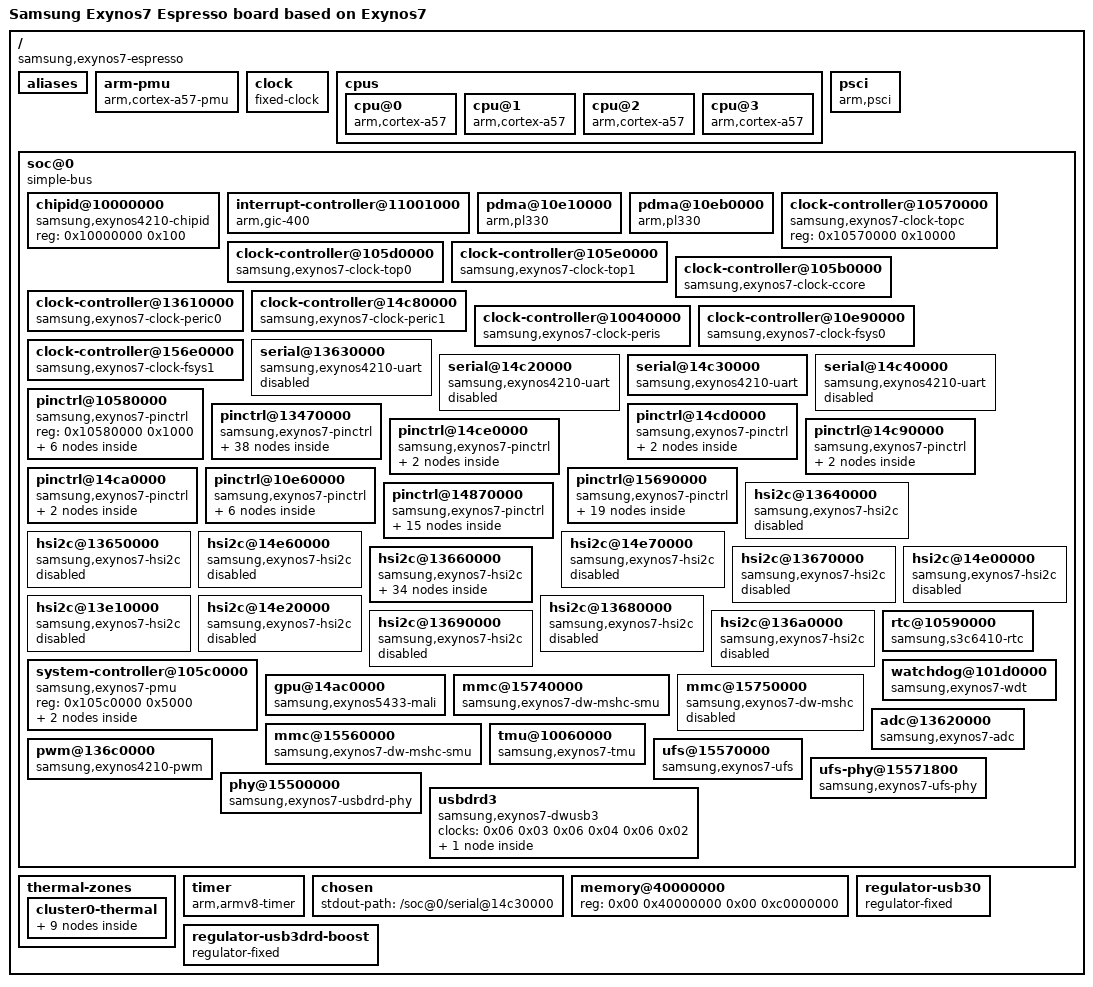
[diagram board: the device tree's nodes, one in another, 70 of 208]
/dts-v1/;

/ {
	compatible = "samsung,exynos7-espresso", "samsung,exynos7";
	interrupt-parent = <0x01>;
	#address-cells = <0x02>;
	#size-cells = <0x02>;
	model = "Samsung Exynos7 Espresso board based on Exynos7";

	aliases {
		pinctrl0 = "/soc@0/pinctrl@10580000";
		pinctrl1 = "/soc@0/pinctrl@13470000";
		pinctrl2 = "/soc@0/pinctrl@14cd0000";
		pinctrl3 = "/soc@0/pinctrl@14ce0000";
		pinctrl4 = "/soc@0/pinctrl@14c90000";
		pinctrl5 = "/soc@0/pinctrl@14ca0000";
		pinctrl6 = "/soc@0/pinctrl@10e60000";
		pinctrl7 = "/soc@0/pinctrl@15690000";
		pinctrl8 = "/soc@0/pinctrl@14870000";
		tmuctrl0 = "/soc@0/tmu@10060000";
		serial0 = "/soc@0/serial@14c30000";
		mshc0 = "/soc@0/mmc@15740000";
		mshc2 = "/soc@0/mmc@15560000";
	};

	arm-pmu {
		compatible = "arm,cortex-a57-pmu";
		interrupts = <0x00 0x38 0x04 0x00 0x39 0x04 0x00 0x3a 0x04 0x00 0x3b 0x04>;
		interrupt-affinity = <0x02 0x03 0x04 0x05>;
	};

	clock {
		compatible = "fixed-clock";
		clock-output-names = "fin_pll";
		#clock-cells = <0x00>;
		clock-frequency = <0x16e3600>;
		phandle = <0x07>;
	};

	cpus {
		#address-cells = <0x01>;
		#size-cells = <0x00>;

		cpu@0 {
			device_type = "cpu";
			compatible = "arm,cortex-a57";
			reg = <0x00>;
			enable-method = "psci";
			phandle = <0x02>;
		};

		cpu@1 {
			device_type = "cpu";
			compatible = "arm,cortex-a57";
			reg = <0x01>;
			enable-method = "psci";
			phandle = <0x03>;
		};

		cpu@2 {
			device_type = "cpu";
			compatible = "arm,cortex-a57";
			reg = <0x02>;
			enable-method = "psci";
			phandle = <0x04>;
		};

		cpu@3 {
			device_type = "cpu";
			compatible = "arm,cortex-a57";
			reg = <0x03>;
			enable-method = "psci";
			phandle = <0x05>;
		};
	};

	psci {
		compatible = "arm,psci";
		method = "smc";
		cpu_off = <0x84000002>;
		cpu_on = <0xc4000003>;
	};

	soc@0 {
		compatible = "simple-bus";
		#address-cells = <0x01>;
		#size-cells = <0x01>;
		ranges = <0x00 0x00 0x00 0x18000000>;
		phandle = <0x39>;

		chipid@10000000 {
			compatible = "samsung,exynos4210-chipid";
			reg = <0x10000000 0x100>;
		};

		interrupt-controller@11001000 {
			compatible = "arm,gic-400";
			#interrupt-cells = <0x03>;
			#address-cells = <0x00>;
			interrupt-controller;
			reg = <0x11001000 0x1000 0x11002000 0x2000 0x11004000 0x2000 0x11006000 0x2000>;
			phandle = <0x01>;
		};

		pdma@10e10000 {
			compatible = "arm,pl330", "arm,primecell";
			reg = <0x10e10000 0x1000>;
			interrupts = <0x00 0xe1 0x04>;
			clocks = <0x06 0x09>;
			clock-names = "apb_pclk";
			#dma-cells = <0x01>;
			#dma-channels = <0x08>;
			#dma-requests = <0x20>;
			phandle = <0x3a>;
		};

		pdma@10eb0000 {
			compatible = "arm,pl330", "arm,primecell";
			reg = <0x10eb0000 0x1000>;
			interrupts = <0x00 0xe2 0x04>;
			clocks = <0x06 0x0a>;
			clock-names = "apb_pclk";
			#dma-cells = <0x01>;
			#dma-channels = <0x08>;
			#dma-requests = <0x20>;
			phandle = <0x3b>;
		};

		clock-controller@10570000 {
			compatible = "samsung,exynos7-clock-topc";
			reg = <0x10570000 0x10000>;
			#clock-cells = <0x01>;
			phandle = <0x08>;
		};

		clock-controller@105d0000 {
			compatible = "samsung,exynos7-clock-top0";
			reg = <0x105d0000 0xb000>;
			#clock-cells = <0x01>;
			clocks = <0x07 0x08 0x02 0x08 0x03 0x08 0x04 0x08 0x05>;
			clock-names = "fin_pll", "dout_sclk_bus0_pll", "dout_sclk_bus1_pll", "dout_sclk_cc_pll", "dout_sclk_mfc_pll";
			phandle = <0x09>;
		};

		clock-controller@105e0000 {
			compatible = "samsung,exynos7-clock-top1";
			reg = <0x105e0000 0xb000>;
			#clock-cells = <0x01>;
			clocks = <0x07 0x08 0x02 0x08 0x03 0x08 0x04 0x08 0x05>;
			clock-names = "fin_pll", "dout_sclk_bus0_pll", "dout_sclk_bus1_pll", "dout_sclk_cc_pll", "dout_sclk_mfc_pll";
			phandle = <0x0a>;
		};

		clock-controller@105b0000 {
			compatible = "samsung,exynos7-clock-ccore";
			reg = <0x105b0000 0xd00>;
			#clock-cells = <0x01>;
			clocks = <0x07 0x08 0x06>;
			clock-names = "fin_pll", "dout_aclk_ccore_133";
			phandle = <0x1c>;
		};

		clock-controller@13610000 {
			compatible = "samsung,exynos7-clock-peric0";
			reg = <0x13610000 0xd00>;
			#clock-cells = <0x01>;
			clocks = <0x07 0x09 0x02 0x09 0x03>;
			clock-names = "fin_pll", "dout_aclk_peric0_66", "sclk_uart0";
			phandle = <0x0b>;
		};

		clock-controller@14c80000 {
			compatible = "samsung,exynos7-clock-peric1";
			reg = <0x14c80000 0xd00>;
			#clock-cells = <0x01>;
			clocks = <0x07 0x09 0x01 0x09 0x04 0x09 0x05 0x09 0x06>;
			clock-names = "fin_pll", "dout_aclk_peric1_66", "sclk_uart1", "sclk_uart2", "sclk_uart3";
			phandle = <0x0c>;
		};

		clock-controller@10040000 {
			compatible = "samsung,exynos7-clock-peris";
			reg = <0x10040000 0xd00>;
			#clock-cells = <0x01>;
			clocks = <0x07 0x08 0x01>;
			clock-names = "fin_pll", "dout_aclk_peris_66";
			phandle = <0x1e>;
		};

		clock-controller@10e90000 {
			compatible = "samsung,exynos7-clock-fsys0";
			reg = <0x10e90000 0xd00>;
			#clock-cells = <0x01>;
			clocks = <0x07 0x0a 0x02 0x0a 0x03>;
			clock-names = "fin_pll", "dout_aclk_fsys0_200", "dout_sclk_mmc2";
			phandle = <0x06>;
		};

		clock-controller@156e0000 {
			compatible = "samsung,exynos7-clock-fsys1";
			reg = <0x156e0000 0xd00>;
			#clock-cells = <0x01>;
			clocks = <0x07 0x0a 0x01 0x0a 0x05 0x0a 0x04 0x0a 0x0e 0x0a 0x10 0x0a 0x11>;
			clock-names = "fin_pll", "dout_aclk_fsys1_200", "dout_sclk_mmc0", "dout_sclk_mmc1", "dout_sclk_ufsunipro20", "dout_sclk_phy_fsys1", "dout_sclk_phy_fsys1_26m";
			phandle = <0x20>;
		};

		serial@13630000 {
			compatible = "samsung,exynos4210-uart";
			reg = <0x13630000 0x100>;
			interrupts = <0x00 0x1b8 0x04>;
			clocks = <0x0b 0x01 0x0b 0x02>;
			clock-names = "uart", "clk_uart_baud0";
			status = "disabled";
			phandle = <0x3c>;
		};

		serial@14c20000 {
			compatible = "samsung,exynos4210-uart";
			reg = <0x14c20000 0x100>;
			interrupts = <0x00 0x1c8 0x04>;
			clocks = <0x0c 0x01 0x0c 0x04>;
			clock-names = "uart", "clk_uart_baud0";
			status = "disabled";
			phandle = <0x3d>;
		};

		serial@14c30000 {
			compatible = "samsung,exynos4210-uart";
			reg = <0x14c30000 0x100>;
			interrupts = <0x00 0x1c9 0x04>;
			clocks = <0x0c 0x02 0x0c 0x05>;
			clock-names = "uart", "clk_uart_baud0";
			status = "okay";
			phandle = <0x3e>;
		};

		serial@14c40000 {
			compatible = "samsung,exynos4210-uart";
			reg = <0x14c40000 0x100>;
			interrupts = <0x00 0x1ca 0x04>;
			clocks = <0x0c 0x03 0x0c 0x06>;
			clock-names = "uart", "clk_uart_baud0";
			status = "disabled";
			phandle = <0x3f>;
		};

		pinctrl@10580000 {
			compatible = "samsung,exynos7-pinctrl";
			reg = <0x10580000 0x1000>;
			phandle = <0x40>;

			wakeup-interrupt-controller {
				compatible = "samsung,exynos7-wakeup-eint";
				interrupt-parent = <0x01>;
				interrupts = <0x00 0x10 0x04>;
			};

			gpa0 {
				gpio-controller;
				#gpio-cells = <0x02>;
				interrupt-controller;
				interrupt-parent = <0x01>;
				#interrupt-cells = <0x02>;
				interrupts = <0x00 0x00 0x04 0x00 0x01 0x04 0x00 0x02 0x04 0x00 0x03 0x04 0x00 0x04 0x04 0x00 0x05 0x04 0x00 0x06 0x04 0x00 0x07 0x04>;
				phandle = <0x12>;
			};

			gpa1 {
				gpio-controller;
				#gpio-cells = <0x02>;
				interrupt-controller;
				interrupt-parent = <0x01>;
				#interrupt-cells = <0x02>;
				interrupts = <0x00 0x08 0x04 0x00 0x09 0x04 0x00 0x0a 0x04 0x00 0x0b 0x04 0x00 0x0c 0x04 0x00 0x0d 0x04 0x00 0x0e 0x04 0x00 0x0f 0x04>;
				phandle = <0x41>;
			};

			gpa2 {
				gpio-controller;
				#gpio-cells = <0x02>;
				interrupt-controller;
				#interrupt-cells = <0x02>;
				phandle = <0x42>;
			};

			gpa3 {
				gpio-controller;
				#gpio-cells = <0x02>;
				interrupt-controller;
				#interrupt-cells = <0x02>;
				phandle = <0x43>;
			};

			pmic-irq {
				samsung,pins = "gpa0-2";
				samsung,pin-pud = <0x03>;
				samsung,pin-drv = <0x03>;
				phandle = <0x13>;
			};
		};

		pinctrl@13470000 {
			compatible = "samsung,exynos7-pinctrl";
			reg = <0x13470000 0x1000>;
			interrupts = <0x00 0x17f 0x04>;
			phandle = <0x44>;

			gpb0 {
				gpio-controller;
				#gpio-cells = <0x02>;
				interrupt-controller;
				#interrupt-cells = <0x02>;
				phandle = <0x45>;
			};

			gpc0 {
				gpio-controller;
				#gpio-cells = <0x02>;
				interrupt-controller;
				#interrupt-cells = <0x02>;
				phandle = <0x46>;
			};

			gpc1 {
				gpio-controller;
				#gpio-cells = <0x02>;
				interrupt-controller;
				#interrupt-cells = <0x02>;
				phandle = <0x47>;
			};

			gpc2 {
				gpio-controller;
				#gpio-cells = <0x02>;
				interrupt-controller;
				#interrupt-cells = <0x02>;
				phandle = <0x48>;
			};

			gpc3 {
				gpio-controller;
				#gpio-cells = <0x02>;
				interrupt-controller;
				#interrupt-cells = <0x02>;
				phandle = <0x49>;
			};

			gpd0 {
				gpio-controller;
				#gpio-cells = <0x02>;
				interrupt-controller;
				#interrupt-cells = <0x02>;
				phandle = <0x4a>;
			};

			gpd1 {
				gpio-controller;
				#gpio-cells = <0x02>;
				interrupt-controller;
				#interrupt-cells = <0x02>;
				phandle = <0x4b>;
			};

			gpd2 {
				gpio-controller;
				#gpio-cells = <0x02>;
				interrupt-controller;
				#interrupt-cells = <0x02>;
				phandle = <0x4c>;
			};

			gpd4 {
				gpio-controller;
				#gpio-cells = <0x02>;
				interrupt-controller;
				#interrupt-cells = <0x02>;
				phandle = <0x4d>;
			};

			gpd5 {
				gpio-controller;
				#gpio-cells = <0x02>;
				interrupt-controller;
				#interrupt-cells = <0x02>;
				phandle = <0x4e>;
			};

			gpd6 {
				gpio-controller;
				#gpio-cells = <0x02>;
				interrupt-controller;
				#interrupt-cells = <0x02>;
				phandle = <0x4f>;
			};

			gpd7 {
				gpio-controller;
				#gpio-cells = <0x02>;
				interrupt-controller;
				#interrupt-cells = <0x02>;
				phandle = <0x50>;
			};

			gpd8 {
				gpio-controller;
				#gpio-cells = <0x02>;
				interrupt-controller;
				#interrupt-cells = <0x02>;
				phandle = <0x51>;
			};

			gpg0 {
				gpio-controller;
				#gpio-cells = <0x02>;
				interrupt-controller;
				#interrupt-cells = <0x02>;
				phandle = <0x52>;
			};

			gpg3 {
				gpio-controller;
				#gpio-cells = <0x02>;
				interrupt-controller;
				#interrupt-cells = <0x02>;
				phandle = <0x53>;
			};

			hs-i2c10-bus {
				samsung,pins = "gpb0-1", "gpb0-0";
				samsung,pin-function = <0x02>;
				samsung,pin-pud = <0x03>;
				samsung,pin-drv = <0x00>;
				phandle = <0x19>;
			};

			hs-i2c11-bus {
				samsung,pins = "gpb0-3", "gpb0-2";
				samsung,pin-function = <0x02>;
				samsung,pin-pud = <0x03>;
				samsung,pin-drv = <0x00>;
				phandle = <0x1a>;
			};

			hs-i2c2-bus {
				samsung,pins = "gpd0-3", "gpd0-2";
				samsung,pin-function = <0x03>;
				samsung,pin-pud = <0x03>;
				samsung,pin-drv = <0x00>;
				phandle = <0x0f>;
			};

			uart0-data {
				samsung,pins = "gpd0-0", "gpd0-1";
				samsung,pin-function = <0x02>;
				samsung,pin-pud = <0x00>;
				samsung,pin-drv = <0x00>;
				phandle = <0x54>;
			};

			uart0-fctl {
				samsung,pins = "gpd0-2", "gpd0-3";
				samsung,pin-function = <0x02>;
				samsung,pin-pud = <0x00>;
				samsung,pin-drv = <0x00>;
				phandle = <0x55>;
			};

			uart2-data {
				samsung,pins = "gpd1-4", "gpd1-5";
				samsung,pin-function = <0x02>;
				samsung,pin-pud = <0x00>;
				samsung,pin-drv = <0x00>;
				phandle = <0x56>;
			};

			hs-i2c3-bus {
				samsung,pins = "gpd1-3", "gpd1-2";
				samsung,pin-function = <0x03>;
				samsung,pin-pud = <0x03>;
				samsung,pin-drv = <0x00>;
				phandle = <0x10>;
			};

			uart1-data {
				samsung,pins = "gpd1-0", "gpd1-1";
				samsung,pin-function = <0x02>;
				samsung,pin-pud = <0x00>;
				samsung,pin-drv = <0x00>;
				phandle = <0x57>;
			};

			uart1-fctl {
				samsung,pins = "gpd1-2", "gpd1-3";
				samsung,pin-function = <0x02>;
				samsung,pin-pud = <0x00>;
				samsung,pin-drv = <0x00>;
				phandle = <0x58>;
			};

			hs-i2c0-bus {
				samsung,pins = "gpd2-1", "gpd2-0";
				samsung,pin-function = <0x02>;
				samsung,pin-pud = <0x03>;
				samsung,pin-drv = <0x00>;
				phandle = <0x0d>;
			};

			hs-i2c1-bus {
				samsung,pins = "gpd2-3", "gpd2-2";
				samsung,pin-function = <0x02>;
				samsung,pin-pud = <0x03>;
				samsung,pin-drv = <0x00>;
				phandle = <0x0e>;
			};

			hs-i2c9-bus {
				samsung,pins = "gpd2-7", "gpd2-6";
				samsung,pin-function = <0x03>;
				samsung,pin-pud = <0x03>;
				samsung,pin-drv = <0x00>;
				phandle = <0x18>;
			};

			pwm0-out {
				samsung,pins = "gpd2-4";
				samsung,pin-function = <0x02>;
				samsung,pin-pud = <0x00>;
				samsung,pin-drv = <0x00>;
				phandle = <0x59>;
			};

			pwm1-out {
				samsung,pins = "gpd2-5";
				samsung,pin-function = <0x02>;
				samsung,pin-pud = <0x00>;
				samsung,pin-drv = <0x00>;
				phandle = <0x5a>;
			};

			pwm2-out {
				samsung,pins = "gpd2-6";
				samsung,pin-function = <0x02>;
				samsung,pin-pud = <0x00>;
				samsung,pin-drv = <0x00>;
				phandle = <0x5b>;
			};

			pwm3-out {
				samsung,pins = "gpd2-7";
				samsung,pin-function = <0x02>;
				samsung,pin-pud = <0x00>;
				samsung,pin-drv = <0x00>;
				phandle = <0x5c>;
			};

			hs-i2c8-bus {
				samsung,pins = "gpd5-3", "gpd5-2";
				samsung,pin-function = <0x03>;
				samsung,pin-pud = <0x03>;
				samsung,pin-drv = <0x00>;
				phandle = <0x17>;
			};

			uart3-data {
				samsung,pins = "gpd5-0", "gpd5-1";
				samsung,pin-function = <0x03>;
				samsung,pin-pud = <0x00>;
				samsung,pin-drv = <0x00>;
				phandle = <0x5d>;
			};

			spi2-bus {
				samsung,pins = "gpd5-0", "gpd5-1", "gpd5-2", "gpd5-3";
				samsung,pin-function = <0x02>;
				samsung,pin-pud = <0x03>;
				samsung,pin-drv = <0x00>;
				phandle = <0x5e>;
			};

			spi1-bus {
				samsung,pins = "gpd6-2", "gpd6-3", "gpd6-4", "gpd6-5";
				samsung,pin-function = <0x02>;
				samsung,pin-pud = <0x03>;
				samsung,pin-drv = <0x00>;
				phandle = <0x5f>;
			};

			spi0-bus {
				samsung,pins = "gpd8-0", "gpd8-1", "gpd6-0", "gpd6-1";
				samsung,pin-function = <0x02>;
				samsung,pin-pud = <0x03>;
				samsung,pin-drv = <0x00>;
				phandle = <0x60>;
			};

			hs-i2c4-bus {
				samsung,pins = "gpg3-1", "gpg3-0";
				samsung,pin-function = <0x02>;
				samsung,pin-pud = <0x03>;
				samsung,pin-drv = <0x00>;
				phandle = <0x11>;
			};

			hs-i2c5-bus {
				samsung,pins = "gpg3-3", "gpg3-2";
				samsung,pin-function = <0x02>;
				samsung,pin-pud = <0x03>;
				samsung,pin-drv = <0x00>;
				phandle = <0x14>;
			};
		};

		pinctrl@14cd0000 {
			compatible = "samsung,exynos7-pinctrl";
			reg = <0x14cd0000 0x1000>;
			interrupts = <0x00 0x1d9 0x04>;
			phandle = <0x61>;

			gpj0 {
				gpio-controller;
				#gpio-cells = <0x02>;
				interrupt-controller;
				#interrupt-cells = <0x02>;
				phandle = <0x62>;
			};

			hs-i2c6-bus {
				samsung,pins = "gpj0-1", "gpj0-0";
				samsung,pin-function = <0x02>;
				samsung,pin-pud = <0x03>;
				samsung,pin-drv = <0x00>;
				phandle = <0x15>;
			};
		};

		pinctrl@14ce0000 {
			compatible = "samsung,exynos7-pinctrl";
			reg = <0x14ce0000 0x1000>;
			interrupts = <0x00 0x1da 0x04>;
			phandle = <0x63>;

			gpj1 {
				gpio-controller;
				#gpio-cells = <0x02>;
				interrupt-controller;
				#interrupt-cells = <0x02>;
				phandle = <0x64>;
			};

			hs-i2c7-bus {
				samsung,pins = "gpj1-1", "gpj1-0";
				samsung,pin-function = <0x02>;
				samsung,pin-pud = <0x03>;
				samsung,pin-drv = <0x00>;
				phandle = <0x16>;
			};
		};

		pinctrl@14c90000 {
			compatible = "samsung,exynos7-pinctrl";
			reg = <0x14c90000 0x1000>;
			interrupts = <0x00 0x1db 0x04>;
			phandle = <0x65>;

			gpg4 {
				gpio-controller;
				#gpio-cells = <0x02>;
				interrupt-controller;
				#interrupt-cells = <0x02>;
				phandle = <0x66>;
			};

			spi3-bus {
				samsung,pins = "gpg4-0", "gpg4-1", "gpg4-2", "gpg4-3";
				samsung,pin-function = <0x02>;
				samsung,pin-pud = <0x03>;
				samsung,pin-drv = <0x00>;
				phandle = <0x67>;
			};
		};

		pinctrl@14ca0000 {
			compatible = "samsung,exynos7-pinctrl";
			reg = <0x14ca0000 0x1000>;
			interrupts = <0x00 0x1dc 0x04>;
			phandle = <0x68>;

			gpv7 {
				gpio-controller;
				#gpio-cells = <0x02>;
				interrupt-controller;
				#interrupt-cells = <0x02>;
				phandle = <0x69>;
			};

			spi4-bus {
				samsung,pins = "gpv7-0", "gpv7-1", "gpv7-2", "gpv7-3";
				samsung,pin-function = <0x02>;
				samsung,pin-pud = <0x03>;
				samsung,pin-drv = <0x00>;
				phandle = <0x6a>;
			};
		};

		pinctrl@10e60000 {
			compatible = "samsung,exynos7-pinctrl";
			reg = <0x10e60000 0x1000>;
			interrupts = <0x00 0xdd 0x04>;
			phandle = <0x6b>;

			gpr4 {
				gpio-controller;
				#gpio-cells = <0x02>;
				interrupt-controller;
				#interrupt-cells = <0x02>;
				phandle = <0x6c>;
			};

			sd2-clk {
				samsung,pins = "gpr4-0";
				samsung,pin-function = <0x02>;
				samsung,pin-pud = <0x00>;
				samsung,pin-drv = <0x03>;
				phandle = <0x27>;
			};

			sd2-cmd {
				samsung,pins = "gpr4-1";
				samsung,pin-function = <0x02>;
				samsung,pin-pud = <0x00>;
				samsung,pin-drv = <0x03>;
				phandle = <0x28>;
			};

			sd2-cd {
				samsung,pins = "gpr4-2";
				samsung,pin-function = <0x02>;
				samsung,pin-pud = <0x03>;
				samsung,pin-drv = <0x03>;
				phandle = <0x29>;
			};

			sd2-bus-width1 {
				samsung,pins = "gpr4-3";
				samsung,pin-function = <0x02>;
				samsung,pin-pud = <0x03>;
				samsung,pin-drv = <0x03>;
				phandle = <0x2a>;
			};

			sd2-bus-width4 {
				samsung,pins = "gpr4-4", "gpr4-5", "gpr4-6";
				samsung,pin-function = <0x02>;
				samsung,pin-pud = <0x03>;
				samsung,pin-drv = <0x03>;
				phandle = <0x2b>;
			};
		};

		pinctrl@15690000 {
			compatible = "samsung,exynos7-pinctrl";
			reg = <0x15690000 0x1000>;
			interrupts = <0x00 0xcb 0x04>;
			phandle = <0x6d>;

			gpr0 {
				gpio-controller;
				#gpio-cells = <0x02>;
				interrupt-controller;
				#interrupt-cells = <0x02>;
				phandle = <0x6e>;
			};

			gpr1 {
				gpio-controller;
				#gpio-cells = <0x02>;
				interrupt-controller;
				#interrupt-cells = <0x02>;
				phandle = <0x6f>;
			};

			gpr2 {
				gpio-controller;
				#gpio-cells = <0x02>;
				interrupt-controller;
				#interrupt-cells = <0x02>;
				phandle = <0x70>;
			};

			gpr3 {
				gpio-controller;
				#gpio-cells = <0x02>;
				interrupt-controller;
				#interrupt-cells = <0x02>;
				phandle = <0x71>;
			};

			sd0-clk {
				samsung,pins = "gpr0-0";
				samsung,pin-function = <0x02>;
				samsung,pin-pud = <0x00>;
				samsung,pin-drv = <0x04>;
				phandle = <0x21>;
			};

			sd0-cmd {
				samsung,pins = "gpr0-1";
				samsung,pin-function = <0x02>;
				samsung,pin-pud = <0x03>;
				samsung,pin-drv = <0x04>;
				phandle = <0x22>;
			};

			sd0-ds {
				samsung,pins = "gpr0-2";
				samsung,pin-function = <0x02>;
				samsung,pin-pud = <0x01>;
				samsung,pin-drv = <0x04>;
				phandle = <0x72>;
			};

			sd0-qrdy {
				samsung,pins = "gpr0-3";
				samsung,pin-function = <0x02>;
				samsung,pin-pud = <0x01>;
				samsung,pin-drv = <0x04>;
				phandle = <0x23>;
			};

			sd0-bus-width1 {
				samsung,pins = "gpr1-0";
				samsung,pin-function = <0x02>;
				samsung,pin-pud = <0x03>;
				samsung,pin-drv = <0x04>;
				phandle = <0x24>;
			};

			sd0-bus-width4 {
				samsung,pins = "gpr1-1", "gpr1-2", "gpr1-3";
				samsung,pin-function = <0x02>;
				samsung,pin-pud = <0x03>;
				samsung,pin-drv = <0x04>;
				phandle = <0x25>;
			};

			sd0-bus-width8 {
				samsung,pins = "gpr1-4", "gpr1-5", "gpr1-6", "gpr1-7";
				samsung,pin-function = <0x02>;
				samsung,pin-pud = <0x03>;
				samsung,pin-drv = <0x04>;
				phandle = <0x26>;
			};

			sd1-clk {
				samsung,pins = "gpr2-0";
				samsung,pin-function = <0x02>;
				samsung,pin-pud = <0x00>;
				samsung,pin-drv = <0x02>;
				phandle = <0x73>;
			};

			sd1-cmd {
				samsung,pins = "gpr2-1";
				samsung,pin-function = <0x02>;
				samsung,pin-pud = <0x00>;
				samsung,pin-drv = <0x02>;
				phandle = <0x74>;
			};

			sd1-ds {
				samsung,pins = "gpr2-2";
				samsung,pin-function = <0x02>;
				samsung,pin-pud = <0x01>;
				samsung,pin-drv = <0x06>;
				phandle = <0x75>;
			};

			sd1-qrdy {
				samsung,pins = "gpr2-3";
				samsung,pin-function = <0x02>;
				samsung,pin-pud = <0x01>;
				samsung,pin-drv = <0x06>;
				phandle = <0x76>;
			};

			sd1-int {
				samsung,pins = "gpr2-4";
				samsung,pin-function = <0x02>;
				samsung,pin-pud = <0x01>;
				samsung,pin-drv = <0x06>;
				phandle = <0x77>;
			};

			sd1-bus-width1 {
				samsung,pins = "gpr3-0";
				samsung,pin-function = <0x02>;
				samsung,pin-pud = <0x03>;
				samsung,pin-drv = <0x02>;
				phandle = <0x78>;
			};

			sd1-bus-width4 {
				samsung,pins = "gpr3-1", "gpr3-2", "gpr3-3";
				samsung,pin-function = <0x02>;
				samsung,pin-pud = <0x03>;
				samsung,pin-drv = <0x02>;
				phandle = <0x79>;
			};

			sd1-bus-width8 {
				samsung,pins = "gpr3-4", "gpr3-5", "gpr3-6", "gpr3-7";
				samsung,pin-function = <0x02>;
				samsung,pin-pud = <0x03>;
				samsung,pin-drv = <0x02>;
				phandle = <0x7a>;
			};
		};

		pinctrl@14870000 {
			compatible = "samsung,exynos7-pinctrl";
			reg = <0x14870000 0x1000>;
			interrupts = <0x00 0x180 0x04>;
			phandle = <0x7b>;

			gpf0 {
				gpio-controller;
				#gpio-cells = <0x02>;
				interrupt-controller;
				#interrupt-cells = <0x02>;
				phandle = <0x7c>;
			};

			gpf1 {
				gpio-controller;
				#gpio-cells = <0x02>;
				interrupt-controller;
				#interrupt-cells = <0x02>;
				phandle = <0x7d>;
			};

			gpf2 {
				gpio-controller;
				#gpio-cells = <0x02>;
				interrupt-controller;
				#interrupt-cells = <0x02>;
				phandle = <0x7e>;
			};

			gpf3 {
				gpio-controller;
				#gpio-cells = <0x02>;
				interrupt-controller;
				#interrupt-cells = <0x02>;
				phandle = <0x7f>;
			};

			gpf4 {
				gpio-controller;
				#gpio-cells = <0x02>;
				interrupt-controller;
				#interrupt-cells = <0x02>;
				phandle = <0x37>;
			};

			gpf5 {
				gpio-controller;
				#gpio-cells = <0x02>;
				interrupt-controller;
				#interrupt-cells = <0x02>;
				phandle = <0x80>;
			};

			gpg1 {
				gpio-controller;
				#gpio-cells = <0x02>;
				interrupt-controller;
				#interrupt-cells = <0x02>;
				phandle = <0x81>;
			};

			gpg2 {
				gpio-controller;
				#gpio-cells = <0x02>;
				interrupt-controller;
				#interrupt-cells = <0x02>;
				phandle = <0x82>;
			};

			gph1 {
				gpio-controller;
				#gpio-cells = <0x02>;
				interrupt-controller;
				#interrupt-cells = <0x02>;
				phandle = <0x35>;
			};

			gpv6 {
				gpio-controller;
				#gpio-cells = <0x02>;
				interrupt-controller;
				#interrupt-cells = <0x02>;
				phandle = <0x83>;
			};

			spi5-bus {
				samsung,pins = "gpf2-0", "gpf2-1", "gpf2-2", "gpf2-3";
				samsung,pin-function = <0x02>;
				samsung,pin-pud = <0x03>;
				samsung,pin-drv = <0x00>;
				phandle = <0x84>;
			};

			ufs-refclk-out {
				samsung,pins = "gpg2-4";
				samsung,pin-function = <0x02>;
				samsung,pin-pud = <0x00>;
				samsung,pin-drv = <0x02>;
				phandle = <0x2f>;
			};

			ufs-rst-n {
				samsung,pins = "gph1-5";
				samsung,pin-function = <0x02>;
				samsung,pin-pud = <0x03>;
				samsung,pin-drv = <0x00>;
				phandle = <0x2e>;
			};

			usb30-vbus-en {
				samsung,pins = "gph1-1";
				samsung,pin-function = <0x01>;
				samsung,pin-pud = <0x00>;
				samsung,pin-drv = <0x00>;
				phandle = <0x36>;
			};

			usb3drd-boost-en {
				samsung,pins = "gpf4-1";
				samsung,pin-function = <0x01>;
				samsung,pin-pud = <0x00>;
				samsung,pin-drv = <0x00>;
				phandle = <0x38>;
			};
		};

		hsi2c@13640000 {
			compatible = "samsung,exynos7-hsi2c";
			reg = <0x13640000 0x1000>;
			interrupts = <0x00 0x1b9 0x04>;
			#address-cells = <0x01>;
			#size-cells = <0x00>;
			pinctrl-names = "default";
			pinctrl-0 = <0x0d>;
			clocks = <0x0b 0x03>;
			clock-names = "hsi2c";
			status = "disabled";
			phandle = <0x85>;
		};

		hsi2c@13650000 {
			compatible = "samsung,exynos7-hsi2c";
			reg = <0x13650000 0x1000>;
			interrupts = <0x00 0x1ba 0x04>;
			#address-cells = <0x01>;
			#size-cells = <0x00>;
			pinctrl-names = "default";
			pinctrl-0 = <0x0e>;
			clocks = <0x0b 0x04>;
			clock-names = "hsi2c";
			status = "disabled";
			phandle = <0x86>;
		};

		hsi2c@14e60000 {
			compatible = "samsung,exynos7-hsi2c";
			reg = <0x14e60000 0x1000>;
			interrupts = <0x00 0x1cb 0x04>;
			#address-cells = <0x01>;
			#size-cells = <0x00>;
			pinctrl-names = "default";
			pinctrl-0 = <0x0f>;
			clocks = <0x0c 0x07>;
			clock-names = "hsi2c";
			status = "disabled";
			phandle = <0x87>;
		};

		hsi2c@14e70000 {
			compatible = "samsung,exynos7-hsi2c";
			reg = <0x14e70000 0x1000>;
			interrupts = <0x00 0x1cc 0x04>;
			#address-cells = <0x01>;
			#size-cells = <0x00>;
			pinctrl-names = "default";
			pinctrl-0 = <0x10>;
			clocks = <0x0c 0x08>;
			clock-names = "hsi2c";
			status = "disabled";
			phandle = <0x88>;
		};

		hsi2c@13660000 {
			compatible = "samsung,exynos7-hsi2c";
			reg = <0x13660000 0x1000>;
			interrupts = <0x00 0x1bb 0x04>;
			#address-cells = <0x01>;
			#size-cells = <0x00>;
			pinctrl-names = "default";
			pinctrl-0 = <0x11>;
			clocks = <0x0b 0x05>;
			clock-names = "hsi2c";
			status = "okay";
			samsung,i2c-sda-delay = <0x64>;
			samsung,i2c-max-bus-freq = <0x30d40>;
			phandle = <0x89>;

			s2mps15_pmic@66 {
				compatible = "samsung,s2mps15-pmic";
				reg = <0x66>;
				interrupts = <0x02 0x08>;
				interrupt-parent = <0x12>;
				pinctrl-names = "default";
				pinctrl-0 = <0x13>;
				wakeup-source;

				clocks {
					compatible = "samsung,s2mps13-clk";
					#clock-cells = <0x01>;
					clock-output-names = "s2mps13_ap", "s2mps13_cp", "s2mps13_bt";
					phandle = <0x1d>;
				};

				regulators {

					LDO1 {
						regulator-name = "vdd_ldo1";
						regulator-min-microvolt = <0x7a120>;
						regulator-max-microvolt = <0xdbba0>;
						regulator-always-on;
						regulator-enable-ramp-delay = <0x7d>;
						phandle = <0x8a>;
					};

					LDO2 {
						regulator-name = "vqmmc-sdcard";
						regulator-min-microvolt = <0x18b820>;
						regulator-max-microvolt = <0x325aa0>;
						regulator-always-on;
						regulator-enable-ramp-delay = <0x7d>;
						phandle = <0x2d>;
					};

					LDO3 {
						regulator-name = "vdd_ldo3";
						regulator-min-microvolt = <0x18b820>;
						regulator-max-microvolt = <0x1e3660>;
						regulator-always-on;
						regulator-boot-on;
						regulator-enable-ramp-delay = <0x7d>;
						phandle = <0x8b>;
					};

					LDO4 {
						regulator-name = "vdd_ldo4";
						regulator-min-microvolt = "", "\f5";
						regulator-max-microvolt = <0x10eff0>;
						regulator-always-on;
						regulator-enable-ramp-delay = <0x7d>;
						phandle = <0x8c>;
					};

					LDO5 {
						regulator-name = "vdd_ldo5";
						regulator-min-microvolt = <0x18b820>;
						regulator-max-microvolt = <0x1e3660>;
						regulator-always-on;
						regulator-enable-ramp-delay = <0x7d>;
						phandle = <0x8d>;
					};

					LDO6 {
						regulator-name = "vdd_ldo6";
						regulator-min-microvolt = <0x225510>;
						regulator-max-microvolt = <0x325aa0>;
						regulator-enable-ramp-delay = <0x7d>;
						phandle = <0x8e>;
					};

					LDO7 {
						regulator-name = "vdd_ldo7";
						regulator-min-microvolt = <0xaae60>;
						regulator-max-microvolt = <0x118c30>;
						regulator-enable-ramp-delay = <0x7d>;
						regulator-always-on;
						phandle = <0x8f>;
					};

					LDO8 {
						regulator-name = "vdd_ldo8";
						regulator-min-microvolt = <0xaae60>;
						regulator-max-microvolt = <0xf4240>;
						regulator-enable-ramp-delay = <0x7d>;
						phandle = <0x90>;
					};

					LDO9 {
						regulator-name = "vdd_ldo9";
						regulator-min-microvolt = <0xaae60>;
						regulator-max-microvolt = <0xf4240>;
						regulator-enable-ramp-delay = <0x7d>;
						phandle = <0x91>;
					};

					LDO10 {
						regulator-name = "vdd_ldo10";
						regulator-min-microvolt = <0xaae60>;
						regulator-max-microvolt = <0xf4240>;
						regulator-enable-ramp-delay = <0x7d>;
						phandle = <0x92>;
					};

					LDO11 {
						regulator-name = "vdd_ldo11";
						regulator-min-microvolt = <0xf4240>;
						regulator-max-microvolt = <0x13d620>;
						regulator-always-on;
						regulator-enable-ramp-delay = <0x7d>;
						phandle = <0x93>;
					};

					LDO12 {
						regulator-name = "vdd_ldo12";
						regulator-min-microvolt = <0xf4240>;
						regulator-max-microvolt = <0x13d620>;
						regulator-enable-ramp-delay = <0x7d>;
						regulator-always-on;
						phandle = <0x94>;
					};

					LDO13 {
						regulator-name = "vdd_ldo13";
						regulator-min-microvolt = <0xf4240>;
						regulator-max-microvolt = <0x13d620>;
						regulator-always-on;
						regulator-enable-ramp-delay = <0x7d>;
						phandle = <0x95>;
					};

					LDO14 {
						regulator-name = "vdd_ldo14";
						regulator-min-microvolt = <0x1b7740>;
						regulator-max-microvolt = <0x337f98>;
						regulator-enable-ramp-delay = <0x7d>;
						phandle = <0x96>;
					};

					LDO17 {
						regulator-name = "vmmc-sdcard";
						regulator-min-microvolt = <0x1b7740>;
						regulator-max-microvolt = <0x337f98>;
						regulator-enable-ramp-delay = <0x7d>;
						phandle = <0x2c>;
					};

					LDO18 {
						regulator-name = "vdd_ldo18";
						regulator-min-microvolt = <0x16e360>;
						regulator-max-microvolt = <0x22b6b8>;
						regulator-enable-ramp-delay = <0x7d>;
						phandle = <0x97>;
					};

					LDO19 {
						regulator-name = "vdd_ldo19";
						regulator-min-microvolt = <0x1b7740>;
						regulator-max-microvolt = <0x337f98>;
						regulator-enable-ramp-delay = <0x7d>;
						phandle = <0x98>;
					};

					LDO21 {
						regulator-name = "vdd_ldo21";
						regulator-min-microvolt = <0x1b7740>;
						regulator-max-microvolt = <0x337f98>;
						regulator-enable-ramp-delay = <0x7d>;
						phandle = <0x99>;
					};

					LDO23 {
						regulator-name = "vdd_ldo23";
						regulator-min-microvolt = <0x16e360>;
						regulator-max-microvolt = <0x22b6b8>;
						regulator-enable-ramp-delay = <0x7d>;
						phandle = <0x9a>;
					};

					LDO25 {
						regulator-name = "vdd_ldo25";
						regulator-min-microvolt = <0x1b7740>;
						regulator-max-microvolt = <0x337f98>;
						regulator-enable-ramp-delay = <0x7d>;
						phandle = <0x9b>;
					};

					LDO26 {
						regulator-name = "vdd_ldo26";
						regulator-min-microvolt = <0xaae60>;
						regulator-max-microvolt = <0x166e30>;
						regulator-enable-ramp-delay = <0x7d>;
						phandle = <0x9c>;
					};

					LDO27 {
						regulator-name = "vdd_ldo27";
						regulator-min-microvolt = <0x16e360>;
						regulator-max-microvolt = <0x22b6b8>;
						regulator-enable-ramp-delay = <0x7d>;
						phandle = <0x9d>;
					};

					BUCK1 {
						regulator-name = "vdd_mif";
						regulator-min-microvolt = <0x7a120>;
						regulator-max-microvolt = <0x124f80>;
						regulator-always-on;
						regulator-boot-on;
						regulator-ramp-delay = <0x61a8>;
						regulator-enable-ramp-delay = <0xfa>;
						phandle = <0x9e>;
					};

					BUCK2 {
						regulator-name = "vdd_atlas";
						regulator-min-microvolt = <0x7a120>;
						regulator-max-microvolt = <0x124f80>;
						regulator-always-on;
						regulator-boot-on;
						regulator-ramp-delay = <0x30d4>;
						regulator-enable-ramp-delay = <0xfa>;
						phandle = <0x9f>;
					};

					BUCK4 {
						regulator-name = "vdd_int";
						regulator-min-microvolt = <0x7a120>;
						regulator-max-microvolt = <0x124f80>;
						regulator-always-on;
						regulator-boot-on;
						regulator-ramp-delay = <0x30d4>;
						regulator-enable-ramp-delay = <0xfa>;
						phandle = <0xa0>;
					};

					BUCK5 {
						regulator-name = "vdd_buck5";
						regulator-min-microvolt = <0x7a120>;
						regulator-max-microvolt = <0x13d620>;
						regulator-ramp-delay = <0x61a8>;
						regulator-enable-ramp-delay = <0xfa>;
						phandle = <0xa1>;
					};

					BUCK6 {
						regulator-name = "vdd_g3d";
						regulator-min-microvolt = <0x7a120>;
						regulator-max-microvolt = <0x155cc0>;
						regulator-ramp-delay = <0x30d4>;
						regulator-enable-ramp-delay = <0xfa>;
						phandle = <0x1f>;
					};

					BUCK7 {
						regulator-name = "vdd_buck7";
						regulator-min-microvolt = <0xf4240>;
						regulator-max-microvolt = <0x16e360>;
						regulator-always-on;
						regulator-ramp-delay = <0x61a8>;
						regulator-enable-ramp-delay = <0xfa>;
						phandle = <0xa2>;
					};

					BUCK8 {
						regulator-name = "vdd_buck8";
						regulator-min-microvolt = <0xf4240>;
						regulator-max-microvolt = <0x16e360>;
						regulator-always-on;
						regulator-ramp-delay = <0x61a8>;
						regulator-enable-ramp-delay = <0xfa>;
						phandle = <0xa3>;
					};

					BUCK9 {
						regulator-name = "vdd_buck9";
						regulator-min-microvolt = <0x1b7740>;
						regulator-max-microvolt = <0x200b20>;
						regulator-always-on;
						regulator-ramp-delay = <0x61a8>;
						regulator-enable-ramp-delay = <0xfa>;
						phandle = <0xa4>;
					};

					BUCK10 {
						regulator-name = "vdd_buck10";
						regulator-min-microvolt = <0xf4240>;
						regulator-max-microvolt = <0x2dc6c0>;
						regulator-always-on;
						regulator-ramp-delay = <0x61a8>;
						regulator-enable-ramp-delay = <0xfa>;
						phandle = <0xa5>;
					};
				};
			};
		};

		hsi2c@13670000 {
			compatible = "samsung,exynos7-hsi2c";
			reg = <0x13670000 0x1000>;
			interrupts = <0x00 0x1bc 0x04>;
			#address-cells = <0x01>;
			#size-cells = <0x00>;
			pinctrl-names = "default";
			pinctrl-0 = <0x14>;
			clocks = <0x0b 0x06>;
			clock-names = "hsi2c";
			status = "disabled";
			phandle = <0xa6>;
		};

		hsi2c@14e00000 {
			compatible = "samsung,exynos7-hsi2c";
			reg = <0x14e00000 0x1000>;
			interrupts = <0x00 0x1cd 0x04>;
			#address-cells = <0x01>;
			#size-cells = <0x00>;
			pinctrl-names = "default";
			pinctrl-0 = <0x15>;
			clocks = <0x0c 0x09>;
			clock-names = "hsi2c";
			status = "disabled";
			phandle = <0xa7>;
		};

		hsi2c@13e10000 {
			compatible = "samsung,exynos7-hsi2c";
			reg = <0x13e10000 0x1000>;
			interrupts = <0x00 0x1ce 0x04>;
			#address-cells = <0x01>;
			#size-cells = <0x00>;
			pinctrl-names = "default";
			pinctrl-0 = <0x16>;
			clocks = <0x0c 0x0a>;
			clock-names = "hsi2c";
			status = "disabled";
			phandle = <0xa8>;
		};

		hsi2c@14e20000 {
			compatible = "samsung,exynos7-hsi2c";
			reg = <0x14e20000 0x1000>;
			interrupts = <0x00 0x1cf 0x04>;
			#address-cells = <0x01>;
			#size-cells = <0x00>;
			pinctrl-names = "default";
			pinctrl-0 = <0x17>;
			clocks = <0x0c 0x0b>;
			clock-names = "hsi2c";
			status = "disabled";
			phandle = <0xa9>;
		};

		hsi2c@13680000 {
			compatible = "samsung,exynos7-hsi2c";
			reg = <0x13680000 0x1000>;
			interrupts = <0x00 0x1bd 0x04>;
			#address-cells = <0x01>;
			#size-cells = <0x00>;
			pinctrl-names = "default";
			pinctrl-0 = <0x18>;
			clocks = <0x0b 0x07>;
			clock-names = "hsi2c";
			status = "disabled";
			phandle = <0xaa>;
		};

		hsi2c@13690000 {
			compatible = "samsung,exynos7-hsi2c";
			reg = <0x13690000 0x1000>;
			interrupts = <0x00 0x1be 0x04>;
			#address-cells = <0x01>;
			#size-cells = <0x00>;
			pinctrl-names = "default";
			pinctrl-0 = <0x19>;
			clocks = <0x0b 0x08>;
			clock-names = "hsi2c";
			status = "disabled";
			phandle = <0xab>;
		};

		hsi2c@136a0000 {
			compatible = "samsung,exynos7-hsi2c";
			reg = <0x136a0000 0x1000>;
			interrupts = <0x00 0x1bf 0x04>;
			#address-cells = <0x01>;
			#size-cells = <0x00>;
			pinctrl-names = "default";
			pinctrl-0 = <0x1a>;
			clocks = <0x0b 0x09>;
			clock-names = "hsi2c";
			status = "disabled";
			phandle = <0xac>;
		};

		system-controller@105c0000 {
			compatible = "samsung,exynos7-pmu", "syscon";
			reg = <0x105c0000 0x5000>;
			phandle = <0x1b>;

			syscon-poweroff {
				compatible = "syscon-poweroff";
				regmap = <0x1b>;
				offset = <0x330c>;
				mask = <0x5200>;
				phandle = <0xad>;
			};

			syscon-reboot {
				compatible = "syscon-reboot";
				regmap = <0x1b>;
				offset = <0x400>;
				mask = <0x01>;
				phandle = <0xae>;
			};
		};

		rtc@10590000 {
			compatible = "samsung,s3c6410-rtc";
			reg = <0x10590000 0x100>;
			interrupts = <0x00 0x163 0x04 0x00 0x164 0x04>;
			clocks = <0x1c 0x01 0x1d 0x00>;
			clock-names = "rtc", "rtc_src";
			status = "okay";
			phandle = <0xaf>;
		};

		watchdog@101d0000 {
			compatible = "samsung,exynos7-wdt";
			reg = <0x101d0000 0x100>;
			interrupts = <0x00 0x6e 0x04>;
			clocks = <0x1e 0x03>;
			clock-names = "watchdog";
			samsung,syscon-phandle = <0x1b>;
			status = "okay";
			phandle = <0xb0>;
		};

		gpu@14ac0000 {
			compatible = "samsung,exynos5433-mali", "arm,mali-t760";
			reg = <0x14ac0000 0x5000>;
			interrupts = <0x00 0xf1 0x04 0x00 0xf2 0x04 0x00 0xf0 0x04>;
			interrupt-names = "job", "mmu", "gpu";
			status = "okay";
			mali-supply = <0x1f>;
			phandle = <0xb1>;
		};

		mmc@15740000 {
			compatible = "samsung,exynos7-dw-mshc-smu";
			interrupts = <0x00 0xc9 0x04>;
			#address-cells = <0x01>;
			#size-cells = <0x00>;
			reg = <0x15740000 0x2000>;
			clocks = <0x20 0x02 0x0a 0x08>;
			clock-names = "biu", "ciu";
			fifo-depth = <0x40>;
			status = "okay";
			cap-mmc-highspeed;
			mmc-hs200-1_8v;
			non-removable;
			card-detect-delay = <0xc8>;
			clock-frequency = <0x2faf0800>;
			samsung,dw-mshc-ciu-div = <0x03>;
			samsung,dw-mshc-sdr-timing = <0x00 0x04>;
			samsung,dw-mshc-ddr-timing = <0x00 0x02>;
			pinctrl-names = "default";
			pinctrl-0 = <0x21 0x22 0x23 0x24 0x25 0x26>;
			bus-width = <0x08>;
			phandle = <0xb2>;
		};

		mmc@15750000 {
			compatible = "samsung,exynos7-dw-mshc";
			interrupts = <0x00 0xca 0x04>;
			#address-cells = <0x01>;
			#size-cells = <0x00>;
			reg = <0x15750000 0x2000>;
			clocks = <0x20 0x01 0x0a 0x07>;
			clock-names = "biu", "ciu";
			fifo-depth = <0x40>;
			status = "disabled";
			phandle = <0xb3>;
		};

		mmc@15560000 {
			compatible = "samsung,exynos7-dw-mshc-smu";
			interrupts = <0x00 0xd8 0x04>;
			#address-cells = <0x01>;
			#size-cells = <0x00>;
			reg = <0x15560000 0x2000>;
			clocks = <0x06 0x01 0x0a 0x06>;
			clock-names = "biu", "ciu";
			fifo-depth = <0x40>;
			status = "okay";
			cap-sd-highspeed;
			card-detect-delay = <0xc8>;
			clock-frequency = <0x17d78400>;
			samsung,dw-mshc-ciu-div = <0x03>;
			samsung,dw-mshc-sdr-timing = <0x02 0x03>;
			samsung,dw-mshc-ddr-timing = <0x01 0x02>;
			pinctrl-names = "default";
			pinctrl-0 = <0x27 0x28 0x29 0x2a 0x2b>;
			bus-width = <0x04>;
			vmmc-supply = <0x2c>;
			vqmmc-supply = <0x2d>;
			disable-wp;
			phandle = <0xb4>;
		};

		adc@13620000 {
			compatible = "samsung,exynos7-adc";
			reg = <0x13620000 0x100>;
			interrupts = <0x00 0x1c0 0x04>;
			clocks = <0x0b 0x0c>;
			clock-names = "adc";
			#io-channel-cells = <0x01>;
			io-channel-ranges;
			status = "okay";
			phandle = <0xb5>;
		};

		pwm@136c0000 {
			compatible = "samsung,exynos4210-pwm";
			reg = <0x136c0000 0x100>;
			interrupts = <0x00 0x1c1 0x04 0x00 0x1c2 0x04 0x00 0x1c3 0x04 0x00 0x1c4 0x04 0x00 0x1c5 0x04>;
			samsung,pwm-outputs = <0x00 0x01 0x02 0x03>;
			#pwm-cells = <0x03>;
			clocks = <0x0b 0x0a>;
			clock-names = "timers";
			phandle = <0xb6>;
		};

		tmu@10060000 {
			compatible = "samsung,exynos7-tmu";
			reg = <0x10060000 0x200>;
			interrupts = <0x00 0x6c 0x04>;
			clocks = <0x1e 0x04 0x1e 0x05>;
			clock-names = "tmu_apbif", "tmu_sclk";
			#thermal-sensor-cells = <0x00>;
			phandle = <0x34>;
		};

		ufs@15570000 {
			compatible = "samsung,exynos7-ufs";
			reg = <0x15570000 0x100 0x15570100 0x100 0x15571000 0x200 0x15572000 0x300>;
			reg-names = "hci", "vs_hci", "unipro", "ufsp";
			interrupts = <0x00 0xc8 0x04>;
			clocks = <0x20 0x06 0x20 0x07>;
			clock-names = "core_clk", "sclk_unipro_main";
			freq-table-hz = <0x00 0x00 0x00 0x00>;
			pinctrl-names = "default";
			pinctrl-0 = <0x2e 0x2f>;
			phys = <0x30>;
			phy-names = "ufs-phy";
			status = "okay";
			phandle = <0xb7>;
		};

		ufs-phy@15571800 {
			compatible = "samsung,exynos7-ufs-phy";
			reg = <0x15571800 0x240>;
			reg-names = "phy-pma";
			samsung,pmu-syscon = <0x1b>;
			#phy-cells = <0x00>;
			clocks = <0x20 0x0c 0x20 0x08 0x20 0x09 0x20 0x0a>;
			clock-names = "ref_clk", "rx1_symbol_clk", "rx0_symbol_clk", "tx0_symbol_clk";
			phandle = <0x30>;
		};

		phy@15500000 {
			compatible = "samsung,exynos7-usbdrd-phy";
			reg = <0x15500000 0x100>;
			clocks = <0x06 0x03 0x06 0x08 0x06 0x06 0x06 0x07 0x06 0x05>;
			clock-names = "phy", "ref", "phy_pipe", "phy_utmi", "itp";
			samsung,pmu-syscon = <0x1b>;
			#phy-cells = <0x01>;
			vbus-supply = <0x31>;
			vbus-boost-supply = <0x32>;
			phandle = <0x33>;
		};

		usbdrd3 {
			compatible = "samsung,exynos7-dwusb3";
			clocks = <0x06 0x03 0x06 0x04 0x06 0x02>;
			clock-names = "usbdrd30", "usbdrd30_susp_clk", "usbdrd30_axius_clk";
			#address-cells = <0x01>;
			#size-cells = <0x01>;
			ranges;

			dwc3@15400000 {
				compatible = "snps,dwc3";
				reg = <0x15400000 0x10000>;
				interrupts = <0x00 0xdf 0x04>;
				phys = <0x33 0x00 0x33 0x01>;
				phy-names = "usb2-phy", "usb3-phy";
			};
		};
	};

	thermal-zones {

		cluster0-thermal {
			polling-delay-passive = <0x00>;
			polling-delay = <0x00>;
			thermal-sensors = <0x34>;
			phandle = <0xb8>;

			trips {

				cpu-alert-0 {
					temperature = <0x124f8>;
					hysteresis = <0x2710>;
					type = "passive";
				};

				cpu-alert-1 {
					temperature = <0x13880>;
					hysteresis = <0x2710>;
					type = "passive";
				};

				cpu-alert-2 {
					temperature = <0x14c08>;
					hysteresis = <0x2710>;
					type = "passive";
				};

				cpu-alert-3 {
					temperature = <0x15f90>;
					hysteresis = <0x2710>;
					type = "passive";
				};

				cpu-alert-4 {
					temperature = <0x17318>;
					hysteresis = <0x2710>;
					type = "passive";
				};

				cpu-alert-5 {
					temperature = <0x186a0>;
					hysteresis = <0x2710>;
					type = "passive";
				};

				cpu-alert-6 {
					temperature = <0x1adb0>;
					hysteresis = <0x2710>;
					type = "passive";
				};

				cpu-crit-0 {
					temperature = <0x1c138>;
					hysteresis = <0x00>;
					type = "critical";
				};
			};
		};
	};

	timer {
		compatible = "arm,armv8-timer";
		interrupts = <0x01 0x0d 0xff08 0x01 0x0e 0xff08 0x01 0x0b 0xff08 0x01 0x0a 0xff08>;
	};

	chosen {
		stdout-path = "/soc@0/serial@14c30000";
	};

	memory@40000000 {
		device_type = "memory";
		reg = <0x00 0x40000000 0x00 0xc0000000>;
	};

	regulator-usb30 {
		compatible = "regulator-fixed";
		regulator-name = "VBUS_5V";
		regulator-min-microvolt = <0x4c4b40>;
		regulator-max-microvolt = <0x4c4b40>;
		gpio = <0x35 0x01 0x00>;
		pinctrl-names = "default";
		pinctrl-0 = <0x36>;
		enable-active-high;
		phandle = <0x31>;
	};

	regulator-usb3drd-boost {
		compatible = "regulator-fixed";
		regulator-name = "VUSB_VBUS_5V";
		regulator-min-microvolt = <0x4c4b40>;
		regulator-max-microvolt = <0x4c4b40>;
		gpio = <0x37 0x01 0x00>;
		pinctrl-names = "default";
		pinctrl-0 = <0x38>;
		enable-active-high;
		phandle = <0x32>;
	};

	__symbols__ {
		fin_pll = "/clock";
		cpu_atlas0 = "/cpus/cpu@0";
		cpu_atlas1 = "/cpus/cpu@1";
		cpu_atlas2 = "/cpus/cpu@2";
		cpu_atlas3 = "/cpus/cpu@3";
		soc = "/soc@0";
		gic = "/soc@0/interrupt-controller@11001000";
		pdma0 = "/soc@0/pdma@10e10000";
		pdma1 = "/soc@0/pdma@10eb0000";
		clock_topc = "/soc@0/clock-controller@10570000";
		clock_top0 = "/soc@0/clock-controller@105d0000";
		clock_top1 = "/soc@0/clock-controller@105e0000";
		clock_ccore = "/soc@0/clock-controller@105b0000";
		clock_peric0 = "/soc@0/clock-controller@13610000";
		clock_peric1 = "/soc@0/clock-controller@14c80000";
		clock_peris = "/soc@0/clock-controller@10040000";
		clock_fsys0 = "/soc@0/clock-controller@10e90000";
		clock_fsys1 = "/soc@0/clock-controller@156e0000";
		serial_0 = "/soc@0/serial@13630000";
		serial_1 = "/soc@0/serial@14c20000";
		serial_2 = "/soc@0/serial@14c30000";
		serial_3 = "/soc@0/serial@14c40000";
		pinctrl_alive = "/soc@0/pinctrl@10580000";
		gpa0 = "/soc@0/pinctrl@10580000/gpa0";
		gpa1 = "/soc@0/pinctrl@10580000/gpa1";
		gpa2 = "/soc@0/pinctrl@10580000/gpa2";
		gpa3 = "/soc@0/pinctrl@10580000/gpa3";
		pmic_irq = "/soc@0/pinctrl@10580000/pmic-irq";
		pinctrl_bus0 = "/soc@0/pinctrl@13470000";
		gpb0 = "/soc@0/pinctrl@13470000/gpb0";
		gpc0 = "/soc@0/pinctrl@13470000/gpc0";
		gpc1 = "/soc@0/pinctrl@13470000/gpc1";
		gpc2 = "/soc@0/pinctrl@13470000/gpc2";
		gpc3 = "/soc@0/pinctrl@13470000/gpc3";
		gpd0 = "/soc@0/pinctrl@13470000/gpd0";
		gpd1 = "/soc@0/pinctrl@13470000/gpd1";
		gpd2 = "/soc@0/pinctrl@13470000/gpd2";
		gpd4 = "/soc@0/pinctrl@13470000/gpd4";
		gpd5 = "/soc@0/pinctrl@13470000/gpd5";
		gpd6 = "/soc@0/pinctrl@13470000/gpd6";
		gpd7 = "/soc@0/pinctrl@13470000/gpd7";
		gpd8 = "/soc@0/pinctrl@13470000/gpd8";
		gpg0 = "/soc@0/pinctrl@13470000/gpg0";
		gpg3 = "/soc@0/pinctrl@13470000/gpg3";
		hs_i2c10_bus = "/soc@0/pinctrl@13470000/hs-i2c10-bus";
		hs_i2c11_bus = "/soc@0/pinctrl@13470000/hs-i2c11-bus";
		hs_i2c2_bus = "/soc@0/pinctrl@13470000/hs-i2c2-bus";
		uart0_data = "/soc@0/pinctrl@13470000/uart0-data";
		uart0_fctl = "/soc@0/pinctrl@13470000/uart0-fctl";
		uart2_data = "/soc@0/pinctrl@13470000/uart2-data";
		hs_i2c3_bus = "/soc@0/pinctrl@13470000/hs-i2c3-bus";
		uart1_data = "/soc@0/pinctrl@13470000/uart1-data";
		uart1_fctl = "/soc@0/pinctrl@13470000/uart1-fctl";
		hs_i2c0_bus = "/soc@0/pinctrl@13470000/hs-i2c0-bus";
		hs_i2c1_bus = "/soc@0/pinctrl@13470000/hs-i2c1-bus";
		hs_i2c9_bus = "/soc@0/pinctrl@13470000/hs-i2c9-bus";
		pwm0_out = "/soc@0/pinctrl@13470000/pwm0-out";
		pwm1_out = "/soc@0/pinctrl@13470000/pwm1-out";
		pwm2_out = "/soc@0/pinctrl@13470000/pwm2-out";
		pwm3_out = "/soc@0/pinctrl@13470000/pwm3-out";
		hs_i2c8_bus = "/soc@0/pinctrl@13470000/hs-i2c8-bus";
		uart3_data = "/soc@0/pinctrl@13470000/uart3-data";
		spi2_bus = "/soc@0/pinctrl@13470000/spi2-bus";
		spi1_bus = "/soc@0/pinctrl@13470000/spi1-bus";
		spi0_bus = "/soc@0/pinctrl@13470000/spi0-bus";
		hs_i2c4_bus = "/soc@0/pinctrl@13470000/hs-i2c4-bus";
		hs_i2c5_bus = "/soc@0/pinctrl@13470000/hs-i2c5-bus";
		pinctrl_nfc = "/soc@0/pinctrl@14cd0000";
		gpj0 = "/soc@0/pinctrl@14cd0000/gpj0";
		hs_i2c6_bus = "/soc@0/pinctrl@14cd0000/hs-i2c6-bus";
		pinctrl_touch = "/soc@0/pinctrl@14ce0000";
		gpj1 = "/soc@0/pinctrl@14ce0000/gpj1";
		hs_i2c7_bus = "/soc@0/pinctrl@14ce0000/hs-i2c7-bus";
		pinctrl_ff = "/soc@0/pinctrl@14c90000";
		gpg4 = "/soc@0/pinctrl@14c90000/gpg4";
		spi3_bus = "/soc@0/pinctrl@14c90000/spi3-bus";
		pinctrl_ese = "/soc@0/pinctrl@14ca0000";
		gpv7 = "/soc@0/pinctrl@14ca0000/gpv7";
		spi4_bus = "/soc@0/pinctrl@14ca0000/spi4-bus";
		pinctrl_fsys0 = "/soc@0/pinctrl@10e60000";
		gpr4 = "/soc@0/pinctrl@10e60000/gpr4";
		sd2_clk = "/soc@0/pinctrl@10e60000/sd2-clk";
		sd2_cmd = "/soc@0/pinctrl@10e60000/sd2-cmd";
		sd2_cd = "/soc@0/pinctrl@10e60000/sd2-cd";
		sd2_bus1 = "/soc@0/pinctrl@10e60000/sd2-bus-width1";
		sd2_bus4 = "/soc@0/pinctrl@10e60000/sd2-bus-width4";
		pinctrl_fsys1 = "/soc@0/pinctrl@15690000";
		gpr0 = "/soc@0/pinctrl@15690000/gpr0";
		gpr1 = "/soc@0/pinctrl@15690000/gpr1";
		gpr2 = "/soc@0/pinctrl@15690000/gpr2";
		gpr3 = "/soc@0/pinctrl@15690000/gpr3";
		sd0_clk = "/soc@0/pinctrl@15690000/sd0-clk";
		sd0_cmd = "/soc@0/pinctrl@15690000/sd0-cmd";
		sd0_ds = "/soc@0/pinctrl@15690000/sd0-ds";
		sd0_qrdy = "/soc@0/pinctrl@15690000/sd0-qrdy";
		sd0_bus1 = "/soc@0/pinctrl@15690000/sd0-bus-width1";
		sd0_bus4 = "/soc@0/pinctrl@15690000/sd0-bus-width4";
		sd0_bus8 = "/soc@0/pinctrl@15690000/sd0-bus-width8";
		sd1_clk = "/soc@0/pinctrl@15690000/sd1-clk";
		sd1_cmd = "/soc@0/pinctrl@15690000/sd1-cmd";
		sd1_ds = "/soc@0/pinctrl@15690000/sd1-ds";
		sd1_qrdy = "/soc@0/pinctrl@15690000/sd1-qrdy";
		sd1_int = "/soc@0/pinctrl@15690000/sd1-int";
		sd1_bus1 = "/soc@0/pinctrl@15690000/sd1-bus-width1";
		sd1_bus4 = "/soc@0/pinctrl@15690000/sd1-bus-width4";
		sd1_bus8 = "/soc@0/pinctrl@15690000/sd1-bus-width8";
		pinctrl_bus1 = "/soc@0/pinctrl@14870000";
		gpf0 = "/soc@0/pinctrl@14870000/gpf0";
		gpf1 = "/soc@0/pinctrl@14870000/gpf1";
		gpf2 = "/soc@0/pinctrl@14870000/gpf2";
		gpf3 = "/soc@0/pinctrl@14870000/gpf3";
		gpf4 = "/soc@0/pinctrl@14870000/gpf4";
		gpf5 = "/soc@0/pinctrl@14870000/gpf5";
		gpg1 = "/soc@0/pinctrl@14870000/gpg1";
		gpg2 = "/soc@0/pinctrl@14870000/gpg2";
		gph1 = "/soc@0/pinctrl@14870000/gph1";
		gpv6 = "/soc@0/pinctrl@14870000/gpv6";
		spi5_bus = "/soc@0/pinctrl@14870000/spi5-bus";
		ufs_refclk_out = "/soc@0/pinctrl@14870000/ufs-refclk-out";
		ufs_rst_n = "/soc@0/pinctrl@14870000/ufs-rst-n";
		usb30_vbus_en = "/soc@0/pinctrl@14870000/usb30-vbus-en";
		usb3drd_boost_en = "/soc@0/pinctrl@14870000/usb3drd-boost-en";
		hsi2c_0 = "/soc@0/hsi2c@13640000";
		hsi2c_1 = "/soc@0/hsi2c@13650000";
		hsi2c_2 = "/soc@0/hsi2c@14e60000";
		hsi2c_3 = "/soc@0/hsi2c@14e70000";
		hsi2c_4 = "/soc@0/hsi2c@13660000";
		s2mps15_osc = "/soc@0/hsi2c@13660000/s2mps15_pmic@66/clocks";
		ldo1_reg = "/soc@0/hsi2c@13660000/s2mps15_pmic@66/regulators/LDO1";
		ldo2_reg = "/soc@0/hsi2c@13660000/s2mps15_pmic@66/regulators/LDO2";
		ldo3_reg = "/soc@0/hsi2c@13660000/s2mps15_pmic@66/regulators/LDO3";
		ldo4_reg = "/soc@0/hsi2c@13660000/s2mps15_pmic@66/regulators/LDO4";
		ldo5_reg = "/soc@0/hsi2c@13660000/s2mps15_pmic@66/regulators/LDO5";
		ldo6_reg = "/soc@0/hsi2c@13660000/s2mps15_pmic@66/regulators/LDO6";
		ldo7_reg = "/soc@0/hsi2c@13660000/s2mps15_pmic@66/regulators/LDO7";
		ldo8_reg = "/soc@0/hsi2c@13660000/s2mps15_pmic@66/regulators/LDO8";
		ldo9_reg = "/soc@0/hsi2c@13660000/s2mps15_pmic@66/regulators/LDO9";
		ldo10_reg = "/soc@0/hsi2c@13660000/s2mps15_pmic@66/regulators/LDO10";
		ldo11_reg = "/soc@0/hsi2c@13660000/s2mps15_pmic@66/regulators/LDO11";
		ldo12_reg = "/soc@0/hsi2c@13660000/s2mps15_pmic@66/regulators/LDO12";
		ldo13_reg = "/soc@0/hsi2c@13660000/s2mps15_pmic@66/regulators/LDO13";
		ldo14_reg = "/soc@0/hsi2c@13660000/s2mps15_pmic@66/regulators/LDO14";
		ldo17_reg = "/soc@0/hsi2c@13660000/s2mps15_pmic@66/regulators/LDO17";
		ldo18_reg = "/soc@0/hsi2c@13660000/s2mps15_pmic@66/regulators/LDO18";
		ldo19_reg = "/soc@0/hsi2c@13660000/s2mps15_pmic@66/regulators/LDO19";
		ldo21_reg = "/soc@0/hsi2c@13660000/s2mps15_pmic@66/regulators/LDO21";
		ldo23_reg = "/soc@0/hsi2c@13660000/s2mps15_pmic@66/regulators/LDO23";
		ldo25_reg = "/soc@0/hsi2c@13660000/s2mps15_pmic@66/regulators/LDO25";
		ldo26_reg = "/soc@0/hsi2c@13660000/s2mps15_pmic@66/regulators/LDO26";
		ldo27_reg = "/soc@0/hsi2c@13660000/s2mps15_pmic@66/regulators/LDO27";
		buck1_reg = "/soc@0/hsi2c@13660000/s2mps15_pmic@66/regulators/BUCK1";
		buck2_reg = "/soc@0/hsi2c@13660000/s2mps15_pmic@66/regulators/BUCK2";
		buck4_reg = "/soc@0/hsi2c@13660000/s2mps15_pmic@66/regulators/BUCK4";
		buck5_reg = "/soc@0/hsi2c@13660000/s2mps15_pmic@66/regulators/BUCK5";
		buck6_reg = "/soc@0/hsi2c@13660000/s2mps15_pmic@66/regulators/BUCK6";
		buck7_reg = "/soc@0/hsi2c@13660000/s2mps15_pmic@66/regulators/BUCK7";
		buck8_reg = "/soc@0/hsi2c@13660000/s2mps15_pmic@66/regulators/BUCK8";
		buck9_reg = "/soc@0/hsi2c@13660000/s2mps15_pmic@66/regulators/BUCK9";
		buck10_reg = "/soc@0/hsi2c@13660000/s2mps15_pmic@66/regulators/BUCK10";
		hsi2c_5 = "/soc@0/hsi2c@13670000";
		hsi2c_6 = "/soc@0/hsi2c@14e00000";
		hsi2c_7 = "/soc@0/hsi2c@13e10000";
		hsi2c_8 = "/soc@0/hsi2c@14e20000";
		hsi2c_9 = "/soc@0/hsi2c@13680000";
		hsi2c_10 = "/soc@0/hsi2c@13690000";
		hsi2c_11 = "/soc@0/hsi2c@136a0000";
		pmu_system_controller = "/soc@0/system-controller@105c0000";
		poweroff = "/soc@0/system-controller@105c0000/syscon-poweroff";
		reboot = "/soc@0/system-controller@105c0000/syscon-reboot";
		rtc = "/soc@0/rtc@10590000";
		watchdog = "/soc@0/watchdog@101d0000";
		gpu = "/soc@0/gpu@14ac0000";
		mmc_0 = "/soc@0/mmc@15740000";
		mmc_1 = "/soc@0/mmc@15750000";
		mmc_2 = "/soc@0/mmc@15560000";
		adc = "/soc@0/adc@13620000";
		pwm = "/soc@0/pwm@136c0000";
		tmuctrl_0 = "/soc@0/tmu@10060000";
		ufs = "/soc@0/ufs@15570000";
		ufs_phy = "/soc@0/ufs-phy@15571800";
		usbdrd_phy = "/soc@0/phy@15500000";
		atlas_thermal = "/thermal-zones/cluster0-thermal";
		usb30_vbus_reg = "/regulator-usb30";
		usb3drd_boost_5v = "/regulator-usb3drd-boost";
	};
};
